# SYS_PD register map
Vendor: Texas Instruments
Peripheral module from a debugger description file (folder omap4430).
Registers are 32-bit, read-only, reset 0x0 unless marked. A register's access mark holds for its fields unless they carry their own. Offsets are as the file gives them; lines under a group give offsets from that group; [hi:lo] are bit positions; {n}, {i} and the like mark numbered series; 'fields as' and 'values as' point back to an identical list; <NAME> marks a mode.

## SYS_PD
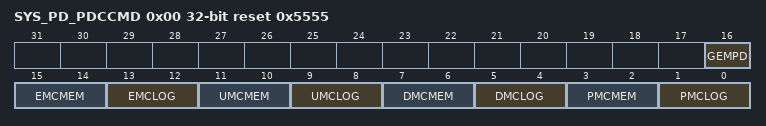
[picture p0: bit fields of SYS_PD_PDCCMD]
0x00 SYS_PD_PDCCMD access per field reset 0x5555 — Power-Down Command Register
  [16] GEMPD rw — Power-down during IDLE:GEMPD = 0: Normal operation. Do not power-down CPU or GEM when CPU is IDLE.GEMPD = 1: Sleep mode. Power-down CPU and GEM when CPU enters IDLE state
  [15:14] EMCMEM rw — SRAM Sleep Modes Determines the RAM sleep modes used by the EMC for powering-down internal memories.
    0=No sleep mode supported; 1=Sleep mode 1; 2=EMCMEM_2_w (Sleep mode 2 - equivalent to sleep mode 1); 3=EMCMEM_3_w (Sleep mode 3 - equivalent to sleep mode 1)
  [13:12] EMCLOG rw — Logic Clock Gating Modes. Determines to what degree the EMC gates its clock internally.
    0=No clock gating supported beyond leaf clock gating; 1=Static clock gating of unused modules regions when GEM is active (pmc_pd_pdstat[1:0] = 00) and Static clock gating when GEM is in standby (pmc_pd_pdstat[1:0] = 11)
  [11:10] UMCMEM rw — SRAM Sleep Modes Determines the RAM sleep modes used by the UMC for powering-down L2 pages.
    0=No sleep mode supported; 1=Sleep mode 1; 2=UMCMEM_2_w (Sleep mode 2 - equivalent to sleep mode 1); 3=UMCMEM_3_w (Sleep mode 3 - equivalent to sleep mode 1)
  [9:8] UMCLOG rw — Logic Clock Gating Modes. Determines to what degree the UMC gates its clock internally.
    values as EMCLOG
  [7:6] DMCMEM rw — SRAM Sleep Modes Determines the RAM sleep modes used by the DMC for powering-down L1D pages.
    0=No sleep mode supported; 1=Sleep mode 1; 2=DMCMEM_2_w (Sleep mode 2 - equivalent to sleep mode 1); 3=DMCMEM_3_w (Sleep mode 3 - equivalent to sleep mode 1)
  [5:4] DMCLOG rw — Logic Clock Gating Modes. Determines to what degree the DMC gates its clock internally.
    values as EMCLOG
  [3:2] PMCMEM rw — SRAM Sleep Modes Determines the RAM sleep modes used by the PMC for powering-down L1P pages.
    0=No sleep mode supported; 1=Sleep mode 1; 2=PMCMEM_2_w (Sleep mode 2 - equivalent to sleep mode 1); 3=PMCMEM_3_w (Sleep mode 3 - equivalent to sleep mode 1)
  [1:0] PMCLOG rw — Logic Clock Gating Modes. Determines to what degree the PMC gates its clock internally.
    values as EMCLOG
{0x1000+4i} SYS_PD_UID_i_{i} (i=0..7)
  [31:0] UID — Unique ID
0x2000 SYS_PD_REVID reset not defined — GEM Revision ID Register
  [31:0] REVISION — IP Revision
